# GD32W515 register map
File version: 1.0
CPU: CM33 r0p4, little endian, MPU, FPU, 4 interrupt priority bits
Registers are 32-bit, read-write, reset 0x0 unless marked. A register's access mark holds for its fields unless they carry their own. Offsets are from the block's base; [hi:lo] are bit positions; {n}, {i} and the like mark numbered series.

## TIMER1 — General-level0-timer
Base 0x40000000
Same registers: TIMER2 0x40000400, SEC_TIMER1 0x50000000, SEC_TIMER2 0x50000400
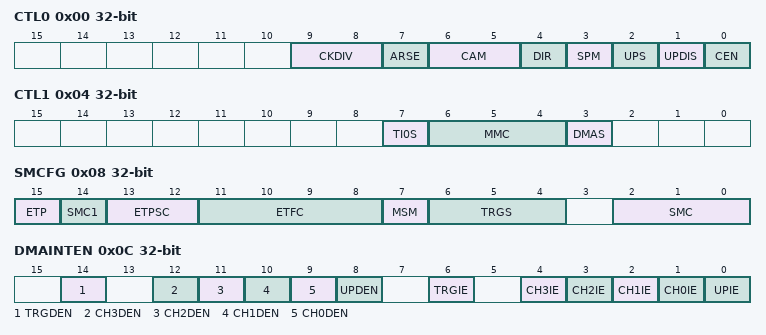
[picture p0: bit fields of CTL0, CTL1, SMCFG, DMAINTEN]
0x00 CTL0 — control register 0
  [9:8] CKDIV — Clock division
  [7] ARSE — Auto-reload preload enable
  [6:5] CAM — Center-aligned mode selection
  [4] DIR — Direction
  [3] SPM — One-pulse mode
  [2] UPS — Update request source
  [1] UPDIS — Update disable
  [0] CEN — Counter enable
0x04 CTL1 — control register 1
  [7] TI0S — TI0 selection
  [6:4] MMC — Master mode selection
  [3] DMAS — Capture/compare DMA selection
0x08 SMCFG — slave mode control register
  [15] ETP — External trigger polarity
  [14] SMC1 — External clock enable
  [13:12] ETPSC — External trigger prescaler
  [11:8] ETFC — External trigger filter
  [7] MSM — Master/Slave mode
  [6:4] TRGS — Trigger selection
  [2:0] SMC — Slave mode selection
0x0C DMAINTEN — DMA/Interrupt enable register
  [14] TRGDEN — Trigger DMA request enable
  [12] CH3DEN — Capture/Compare 3 DMA request enable
  [11] CH2DEN — Capture/Compare 2 DMA request enable
  [10] CH1DEN — Capture/Compare 1 DMA request enable
  [9] CH0DEN — Capture/Compare 1 DMA request enable
  [8] UPDEN — Update DMA request enable
  [6] TRGIE — Trigger interrupt enable
  [n+1] CH{n}IE (n=0..3) — Capture/Compare {n} interrupt enable
  [0] UPIE — Update interrupt enable
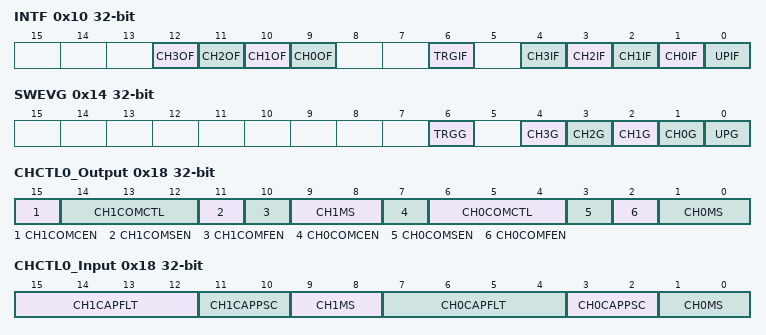
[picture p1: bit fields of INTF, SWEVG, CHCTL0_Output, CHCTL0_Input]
0x10 INTF — interrupt flag register
  [12] CH3OF — Capture/Compare 3 overcapture flag
  [11] CH2OF — Capture/Compare 2 overcapture flag
  [10] CH1OF — Capture/compare 1 overcapture flag
  [9] CH0OF — Capture/Compare 0 overcapture flag
  [6] TRGIF — Trigger interrupt flag
  [4] CH3IF — Capture/Compare 3 interrupt flag
  [3] CH2IF — Capture/Compare 2 interrupt flag
  [2] CH1IF — Capture/Compare 1 interrupt flag
  [1] CH0IF — Capture/compare 0 interrupt flag
  [0] UPIF — Update interrupt flag
0x14 SWEVG wo — event generation register
  [6] TRGG — Trigger generation
  [n+1] CH{n}G (n=0..3) — Capture/compare {n} generation
  [0] UPG — Update generation
0x18 CHCTL0_Output — capture/compare mode register 0 (output mode)
  [15] CH1COMCEN — Output compare 1 clear enable
  [14:12] CH1COMCTL — Output compare 1 mode
  [11] CH1COMSEN — Output compare 1 preload enable
  [10] CH1COMFEN — Output compare 1 fast enable
  [9:8] CH1MS — Capture/Compare 1 selection
  [7] CH0COMCEN — Output compare 0 clear enable
  [6:4] CH0COMCTL — Output compare 0 mode
  [3] CH0COMSEN — Output compare 0 preload enable
  [2] CH0COMFEN — Output compare 0 fast enable
  [1:0] CH0MS — Capture/Compare 0 selection
0x18 CHCTL0_Input (alternate view of CHCTL0_Output) — capture/compare mode register 0 (input mode)
  [15:12] CH1CAPFLT — Input capture 1 filter
  [11:10] CH1CAPPSC — Input capture 1 prescaler
  [9:8] CH1MS — Capture/compare 1 selection
  [7:4] CH0CAPFLT — Input capture 0 filter
  [3:2] CH0CAPPSC — Input capture 0 prescaler
  [1:0] CH0MS — Capture/Compare 0 selection
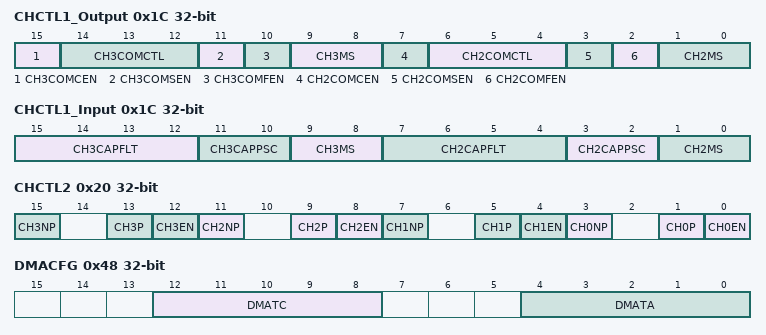
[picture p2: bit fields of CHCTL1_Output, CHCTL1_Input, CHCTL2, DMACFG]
0x1C CHCTL1_Output — capture/compare mode register 1 (output mode)
  [15] CH3COMCEN — Output compare 3 clear enable
  [14:12] CH3COMCTL — Output compare 3 mode
  [11] CH3COMSEN — Output compare 3 preload enable
  [10] CH3COMFEN — Output compare 3 fast enable
  [9:8] CH3MS — Capture/Compare 3 selection
  [7] CH2COMCEN — Output compare 2 clear enable
  [6:4] CH2COMCTL — Output compare 2 mode
  [3] CH2COMSEN — Output compare 2 preload enable
  [2] CH2COMFEN — Output compare 2 fast enable
  [1:0] CH2MS — Capture/Compare 2 selection
0x1C CHCTL1_Input (alternate view of CHCTL1_Output) — capture/compare mode register 1 (input mode)
  [15:12] CH3CAPFLT — Input capture 3 filter
  [11:10] CH3CAPPSC — Input capture 3 prescaler
  [9:8] CH3MS — Capture/Compare 3 selection
  [7:4] CH2CAPFLT — Input capture 2 filter
  [3:2] CH2CAPPSC — Input capture 2 prescaler
  [1:0] CH2MS — Capture/Compare 2 selection
0x20 CHCTL2 — capture/compare enable register
  [4n+3] CH{n}NP (n=0..3) — Capture/Compare {n} output Polarity
  [4n+1] CH{n}P (n=0..3) — Capture/Compare {n} output Polarity
  [4n] CH{n}EN (n=0..3) — Capture/Compare {n} output enable
0x24 CNT — counter
  [31:0] CNT — counter value
0x28 PSC — prescaler
  [15:0] PSC — Prescaler value
0x2C CAR — auto-reload register
  [31:0] CARL — Low Auto-reload value
0x34 CH0CV — capture/compare register 1
  [31:0] CH0VAL — Low Capture/Compare 1 value
0x38 CH1CV — capture/compare register 2
  [31:0] CH1VAL — Low Capture/Compare 2 value
0x3C CH2CV — capture/compare register 2
  [31:0] CH2VAL — High Capture/Compare value (TIM2 only)
0x40 CH3CV — capture/compare register 3
  [31:0] CH3VAL — High Capture/Compare value (TIM2 only)
0x48 DMACFG — DMA control register
  [12:8] DMATC — DMA burst length
  [4:0] DMATA — DMA base address
0x4C DMATB — DMA address for full transfer
  [31:0] DMATB — DMA register for burst accesses
0xFC CFG — Configuration
  [1] CHVSEL — Write CHxVAL register selection

## TIMER3 — General-level0-timer
Base 0x40000800
Same registers: SEC_TIMER3 0x50000800
Registers as TIMER1; these are added or differ:
0x24 CNT — counter
  [15:0] CNT — counter value
0x2C CAR — auto-reload register
  [15:0] CARL — Low Auto-reload value
0x34 CH0CV — capture/compare register 1
  [15:0] CH0VAL — Low Capture/Compare 1 value
0x38 CH1CV — capture/compare register 2
  [15:0] CH1VAL — Low Capture/Compare 2 value
0x3C CH2CV — capture/compare register 2
  [15:0] CH2VAL — High Capture/Compare value (TIM2 only)
0x40 CH3CV — capture/compare register 3
  [15:0] CH3VAL — High Capture/Compare value (TIM2 only)
0x4C DMATB — DMA address for full transfer
  [15:0] DMATB — DMA register for burst accesses

## TIMER4 — General-purpose-timers
Base 0x40000C00
Same registers: SEC_TIMER4 0x50000C00
Registers as TIMER3; these are added or differ:
0x50 IRMP — channel input remap
  [7:6] CI3_RMP — channel 3 input remap
